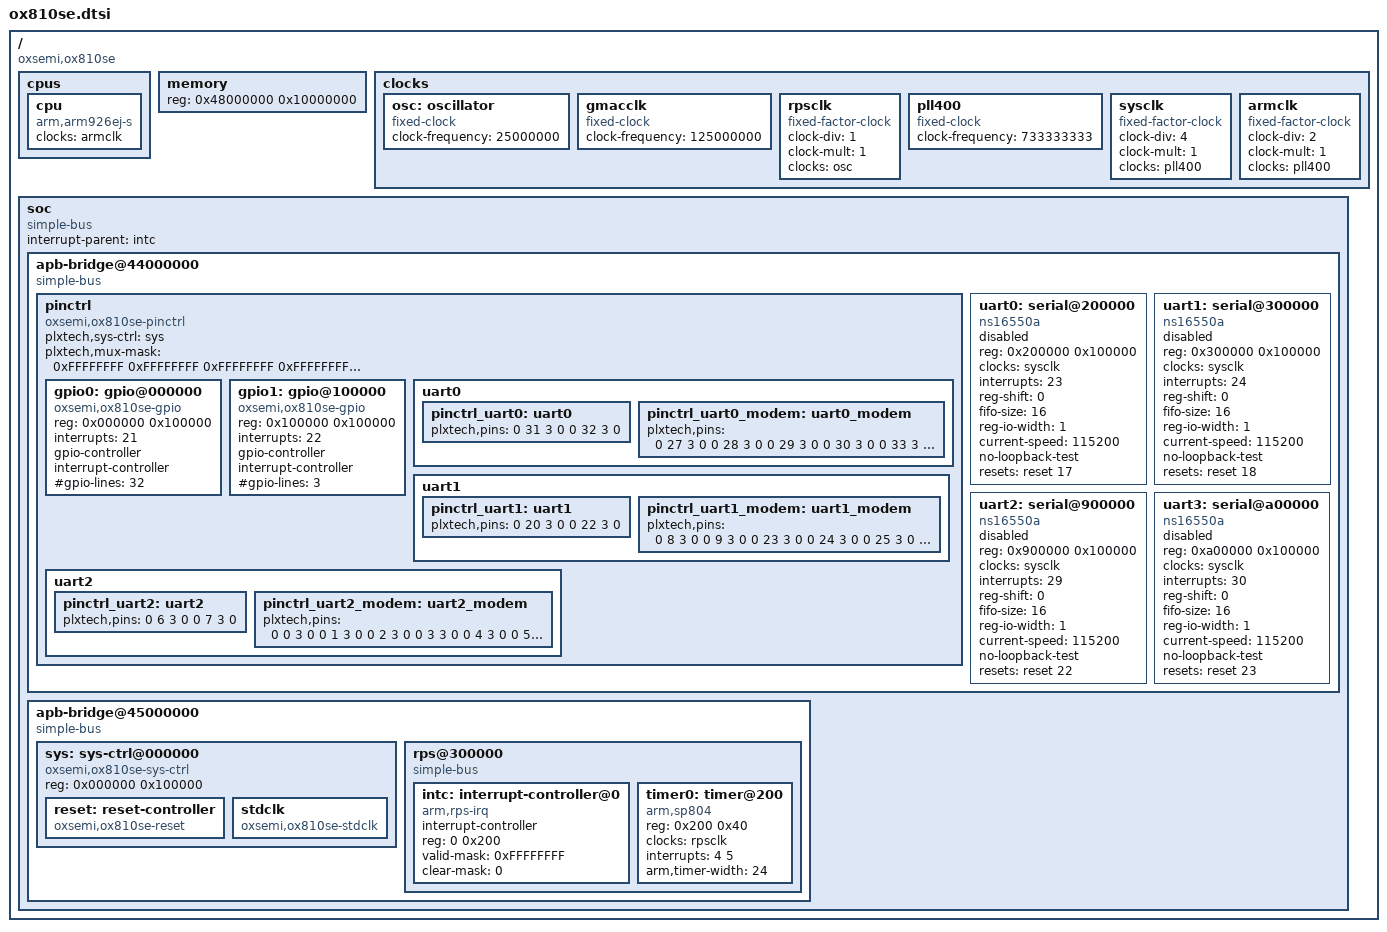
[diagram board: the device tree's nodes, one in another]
/*
 * ox810se.dtsi - Device tree file for Oxford Semiconductor OX810SE SoC
 *
 * Copyright (C) 2016 Neil Armstrong <narmstrong@baylibre.com>
 *
 * Licensed under GPLv2 or later
 */

/include/ "skeleton.dtsi"

/ {
	compatible = "oxsemi,ox810se";

	cpus {
		#address-cells = <0>;
		#size-cells = <0>;

		cpu {
			device_type = "cpu";
			compatible = "arm,arm926ej-s";
			clocks = <&armclk>;
		};
	};

	memory {
		/* Max 256MB @ 0x48000000 */
		reg = <0x48000000 0x10000000>;
	};

	clocks {
		osc: oscillator {
			compatible = "fixed-clock";
			#clock-cells = <0>;
			clock-frequency = <25000000>;
		};

		gmacclk: gmacclk {
			compatible = "fixed-clock";
			#clock-cells = <0>;
			clock-frequency = <125000000>;
		};

		rpsclk: rpsclk {
			compatible = "fixed-factor-clock";
			#clock-cells = <0>;
			clock-div = <1>;
			clock-mult = <1>;
			clocks = <&osc>;
		};

		pll400: pll400 {
			compatible = "fixed-clock";
			#clock-cells = <0>;
			clock-frequency = <733333333>;
		};

		sysclk: sysclk {
			compatible = "fixed-factor-clock";
			#clock-cells = <0>;
			clock-div = <4>;
			clock-mult = <1>;
			clocks = <&pll400>;
		};

		armclk: armclk {
			compatible = "fixed-factor-clock";
			#clock-cells = <0>;
			clock-div = <2>;
			clock-mult = <1>;
			clocks = <&pll400>;
		};
	};

	soc {
		#address-cells = <1>;
		#size-cells = <1>;
		compatible = "simple-bus";
		ranges;
		interrupt-parent = <&intc>;

		apb-bridge@44000000 {
			#address-cells = <1>;
			#size-cells = <1>;
			compatible = "simple-bus";
			ranges = <0 0x44000000 0x1000000>;

			pinctrl: pinctrl {
				compatible = "oxsemi,ox810se-pinctrl", "simple-bus";
				#address-cells = <1>;
				#size-cells = <1>;
				ranges;

				/* Regmap for sys registers */
				plxtech,sys-ctrl = <&sys>;

				/* Default, all-open mux-map */
				plxtech,mux-mask = <
					0xFFFFFFFF 0xFFFFFFFF 0xFFFFFFFF 0xFFFFFFFF 0xFFFFFFFF
					0xFFFFFFFF 0xFFFFFFFF 0xFFFFFFFF 0xFFFFFFFF 0xFFFFFFFF
					>;

				gpio0: gpio@000000 {
					compatible = "oxsemi,ox810se-gpio";
					reg = <0x000000 0x100000>;
					interrupts = <21>;
					#gpio-cells = <2>;
					gpio-controller;
					interrupt-controller;
					#interrupt-cells = <2>;
					#gpio-lines = <32>;
				};

				gpio1: gpio@100000 {
					compatible = "oxsemi,ox810se-gpio";
					reg = <0x100000 0x100000>;
					interrupts = <22>;
					#gpio-cells = <2>;
					gpio-controller;
					interrupt-controller;
					#interrupt-cells = <2>;
					#gpio-lines = <3>;
				};

				uart0 {
					pinctrl_uart0: uart0 {
						plxtech,pins = <0 31 3 0
								0 32 3 0>;
					};
					pinctrl_uart0_modem: uart0_modem {
						plxtech,pins = <0 27 3 0
								0 28 3 0
								0 29 3 0
								0 30 3 0
								0 33 3 0
								0 34 3 0>;
					};
				};

				uart1 {
					pinctrl_uart1: uart1 {
						plxtech,pins = <0 20 3 0
								0 22 3 0>;
					};
					pinctrl_uart1_modem: uart1_modem {
						plxtech,pins = <0 8 3 0
								0 9 3 0
								0 23 3 0
								0 24 3 0
								0 25 3 0
								0 26 3 0>;
					};
				};

				uart2 {
					pinctrl_uart2: uart2 {
						plxtech,pins = <0 6 3 0
								0 7 3 0>;
					};
					pinctrl_uart2_modem: uart2_modem {
						plxtech,pins = <0 0 3 0
								0 1 3 0
								0 2 3 0
								0 3 3 0
								0 4 3 0
								0 5 3 0>;
					};
				};
			};

			uart0: serial@200000 {
			       compatible = "ns16550a";
			       reg = <0x200000 0x100000>;
			       clocks = <&sysclk>;
			       interrupts = <23>;
			       reg-shift = <0>;
			       fifo-size = <16>;
			       reg-io-width = <1>;
			       current-speed = <115200>;
			       no-loopback-test;
			       status = "disabled";
			       resets = <&reset 17>;
			};

			uart1: serial@300000 {
			       compatible = "ns16550a";
			       reg = <0x300000 0x100000>;
			       clocks = <&sysclk>;
			       interrupts = <24>;
			       reg-shift = <0>;
			       fifo-size = <16>;
			       reg-io-width = <1>;
			       current-speed = <115200>;
			       no-loopback-test;
			       status = "disabled";
			       resets = <&reset 18>;
			};

			uart2: serial@900000 {
			       compatible = "ns16550a";
			       reg = <0x900000 0x100000>;
			       clocks = <&sysclk>;
			       interrupts = <29>;
			       reg-shift = <0>;
			       fifo-size = <16>;
			       reg-io-width = <1>;
			       current-speed = <115200>;
			       no-loopback-test;
			       status = "disabled";
			       resets = <&reset 22>;
			};

			uart3: serial@a00000 {
			       compatible = "ns16550a";
			       reg = <0xa00000 0x100000>;
			       clocks = <&sysclk>;
			       interrupts = <30>;
			       reg-shift = <0>;
			       fifo-size = <16>;
			       reg-io-width = <1>;
			       current-speed = <115200>;
			       no-loopback-test;
			       status = "disabled";
			       resets = <&reset 23>;
			};
		};

		apb-bridge@45000000 {
			#address-cells = <1>;
			#size-cells = <1>;
			compatible = "simple-bus";
			ranges = <0 0x45000000 0x1000000>;

			sys: sys-ctrl@000000 {
				compatible = "oxsemi,ox810se-sys-ctrl", "syscon", "simple-mfd";
				reg = <0x000000 0x100000>;

				reset: reset-controller {
					compatible = "oxsemi,ox810se-reset";
					#reset-cells = <1>;
				};

				stdclk: stdclk {
					compatible = "oxsemi,ox810se-stdclk";
					#clock-cells = <1>;
				};
			};

			rps@300000 {
				#address-cells = <1>;
				#size-cells = <1>;
				compatible = "simple-bus";
				ranges = <0 0x300000 0x100000>;

				intc: interrupt-controller@0 {
					compatible = "arm,rps-irq";
					interrupt-controller;
					reg = <0 0x200>;
					#interrupt-cells = <1>;
					valid-mask = <0xFFFFFFFF>;
					clear-mask = <0>;
				};

				timer0: timer@200 {
					compatible = "arm,sp804";
					reg = <0x200 0x40>;
					clocks = <&rpsclk>;
					interrupts = <4 5>;
					arm,timer-width = <24>;
				};
			};
		};
	};
};
